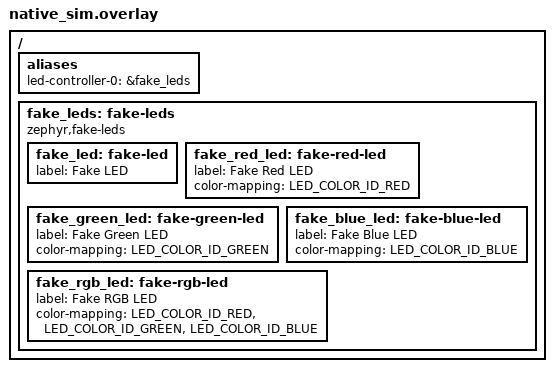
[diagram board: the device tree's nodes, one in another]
/*
 * SPDX-FileCopyrightText: Copyright (c) 2026 Henrik Brix Andersen <henrik@brixandersen.dk>
 *
 * SPDX-License-Identifier: Apache-2.0
 */

#include <zephyr/dt-bindings/led/led.h>

/ {
	aliases {
		led-controller-0 = &fake_leds;
	};

	fake_leds: fake-leds {
		compatible = "zephyr,fake-leds";

		fake_led: fake-led {
			label = "Fake LED";
		};

		fake_red_led: fake-red-led {
			label = "Fake Red LED";
			color-mapping = <LED_COLOR_ID_RED>;
		};

		fake_green_led: fake-green-led {
			label = "Fake Green LED";
			color-mapping = <LED_COLOR_ID_GREEN>;
		};

		fake_blue_led: fake-blue-led {
			label = "Fake Blue LED";
			color-mapping = <LED_COLOR_ID_BLUE>;
		};

		fake_rgb_led: fake-rgb-led {
			label = "Fake RGB LED";
			color-mapping = <LED_COLOR_ID_RED>,
					<LED_COLOR_ID_GREEN>,
					<LED_COLOR_ID_BLUE>;
		};
	};
};
